# ADuCM355 register map
Vendor: Analog Devices; Series: ADuCM355; File version: 1p0
CPU: CM3 r0p1, little endian, no MPU, no FPU, 3 interrupt priority bits
Registers are 32-bit, read-write, reset 0x0 unless marked. A register's access mark holds for its fields unless they carry their own. Offsets are from the block's base; [hi:lo] are bit positions; {n}, {i} and the like mark numbered series; 'fields as' and 'values as' point back to an identical list.

## AFE
Base 0x400C2000
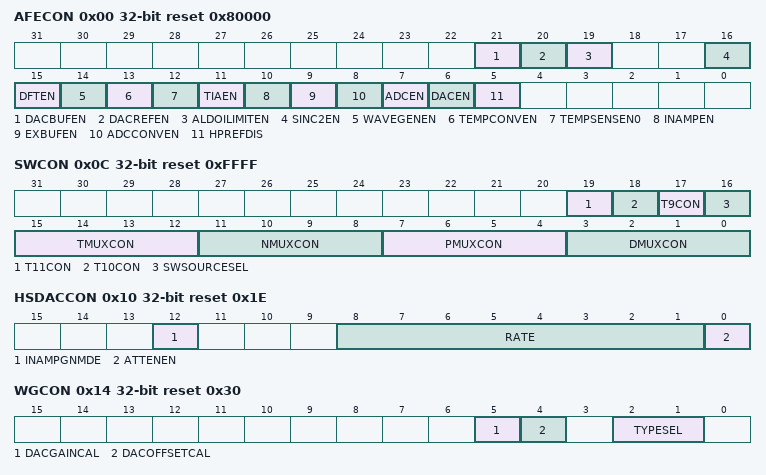
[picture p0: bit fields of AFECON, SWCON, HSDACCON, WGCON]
0x00 AFECON reset 0x80000 — AFE Configuration
  [21] DACBUFEN — Enable DC DAC Buffer
  [20] DACREFEN — High Speed DAC Reference Enable
  [19] ALDOILIMITEN — Analog LDO Current Limiting Enable
  [16] SINC2EN — ADC Output 50/60Hz Filter Enable
  [15] DFTEN — DFT Hardware Accelerator Enable
  [14] WAVEGENEN — Waveform Generator Enable
  [13] TEMPCONVEN — ADC Temp Sensor Convert Enable
  [12] TEMPSENSEN0 — ADC Temperature Sensor Channel Enable
  [11] TIAEN — High Power TIA Enable
  [10] INAMPEN — Enable Excitation Amplifier
  [9] EXBUFEN — Enable Excitation Buffer
  [8] ADCCONVEN — ADC Conversion Start Enable
  [7] ADCEN — ADC Power Enable
  [6] DACEN — High Power DAC Enable
    0=Off (High Power DAC Disabled); 1=On (High Power DAC Enabled)
  [5] HPREFDIS — Disable High Power Reference
0x0C SWCON reset 0xFFFF — Switch Matrix Configuration
  [19] T11CON — Control of T[11]
  [18] T10CON — Control of T[10]
  [17] T9CON — Control of T[9]
  [16] SWSOURCESEL — Switch Control Select
  [15:12] TMUXCON — Control of T Switch MUX.
  [11:8] NMUXCON — Control of N Switch MUX
  [7:4] PMUXCON — Control of P Switch MUX
  [3:0] DMUXCON — Control of D Switch MUX
0x10 HSDACCON reset 0x1E — High Speed DAC Configuration
  [12] INAMPGNMDE — Excitation Amplifier Gain Control
  [8:1] RATE range 0x00000000..0x000000FF — DAC Update Rate
  [0] ATTENEN — PGA Stage Gain Attenuation
0x14 WGCON reset 0x30 — Waveform Generator Configuration
  [5] DACGAINCAL — Bypass DAC Gain
  [4] DACOFFSETCAL — Bypass DAC Offset
  [2:1] TYPESEL — Selects the Type of Waveform
0x30 WGFCW — Waveform Generator - Sinusoid Frequency Control Word
  [23:0] SINEFCW range 0x00000000..0x00FFFFFF — Sinusoid Generator Frequency Control Word
0x34 WGPHASE — Waveform Generator - Sinusoid Phase Offset
  [19:0] SINEOFFSET range 0x00000000..0x000FFFFF — Sinusoid Phase Offset
0x38 WGOFFSET — Waveform Generator - Sinusoid Offset
  [11:0] SINEOFFSET range 0x00000000..0x00000FFF — Sinusoid Offset
0x3C WGAMPLITUDE — Waveform Generator - Sinusoid Amplitude
  [10:0] SINEAMPLITUDE range 0x00000000..0x000007FF — Sinusoid Amplitude
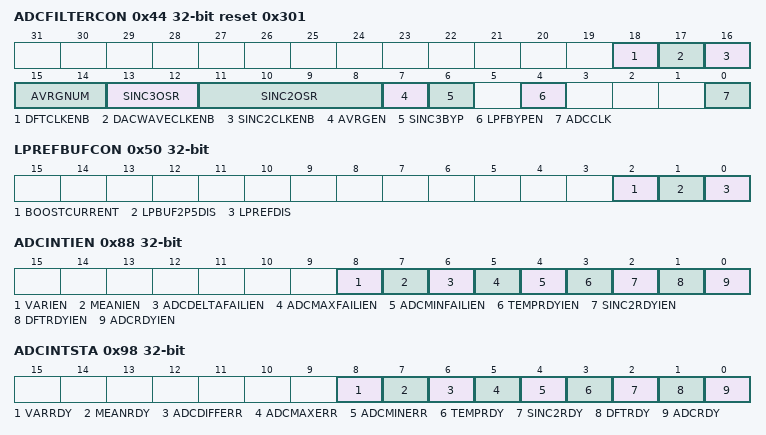
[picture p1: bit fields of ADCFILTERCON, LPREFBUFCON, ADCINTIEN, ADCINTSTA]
0x44 ADCFILTERCON reset 0x301 — ADC Output Filters Configuration
  [18] DFTCLKENB — DFT Clock Enable
  [17] DACWAVECLKENB — DAC Wave Clock Enable
  [16] SINC2CLKENB — SINC2 Filter Clock Enable
  [15:14] AVRGNUM — Number of Samples Averaged
  [13:12] SINC3OSR
  [11:8] SINC2OSR
  [7] AVRGEN — Average Function Enable
  [6] SINC3BYP — SINC3 Filter Bypass
  [4] LPFBYPEN — 50/60Hz Low Pass Filter
  [0] ADCCLK — ADC Data Rate
0x48 HSDACDAT reset 0x800 — HS DAC Code
  [11:0] DACDAT range 0x00000000..0x00000FFF — DAC Code
0x50 LPREFBUFCON
  [2] BOOSTCURRENT — Set: Drive 2 Dac ;Unset Drive 1 Dac, and Save Power
  [1] LPBUF2P5DIS — Low Power Bandgap's Output Buffer
  [0] LPREFDIS — Set This Bit Will Power Down Low Power Bandgap
0x74 ADCDAT — ADC Raw Result
  [15:0] DATA range 0x00000000..0x0000FFFF — ADC Result
0x78 DFTREAL — DFT Result, Real Part
  [17:0] DATA range 0x00000000..0x0003FFFF — DFT Real
0x7C DFTIMAG — DFT Result, Imaginary Part
  [17:0] DATA range 0x00000000..0x0003FFFF — DFT Imaginary
0x80 SINC2DAT — Supply Rejection Filter Result
  [15:0] DATA range 0x00000000..0x0000FFFF — LPF Result
0x84 TEMPSENSDAT — Temperature Sensor Result
  [15:0] DATA range 0x00000000..0x0000FFFF — Temp Sensor
0x88 ADCINTIEN — ADC Interrupt Enable Register
  [8] VARIEN — Variance Interrupt
  [7] MEANIEN — Mean Interrupt
  [6] ADCDELTAFAILIEN — Delta Interrupt
  [5] ADCMAXFAILIEN — ADCMAX Interrupt
  [4] ADCMINFAILIEN — ADCMIN Interrupt
  [3] TEMPRDYIEN — Temp Sensor Interrupt
  [2] SINC2RDYIEN — Low Pass Filter Result Interrupt
  [1] DFTRDYIEN — DFT Result Ready Interrupt
  [0] ADCRDYIEN — ADCDAT Ready Interrupt
0x98 ADCINTSTA — ADC Interrupt Status
  [8] VARRDY — Variance Result Ready
  [7] MEANRDY — Mean Result Ready
  [6] ADCDIFFERR — ADC Delta Ready
  [5] ADCMAXERR — ADC Maximum Value
  [4] ADCMINERR — ADC Minimum Value
  [3] TEMPRDY — Temp Sensor Result Ready
  [2] SINC2RDY — Low Pass Filter Result Status
  [1] DFTRDY — DFT Result Ready Status
  [0] ADCRDY — ADC Result Ready Status
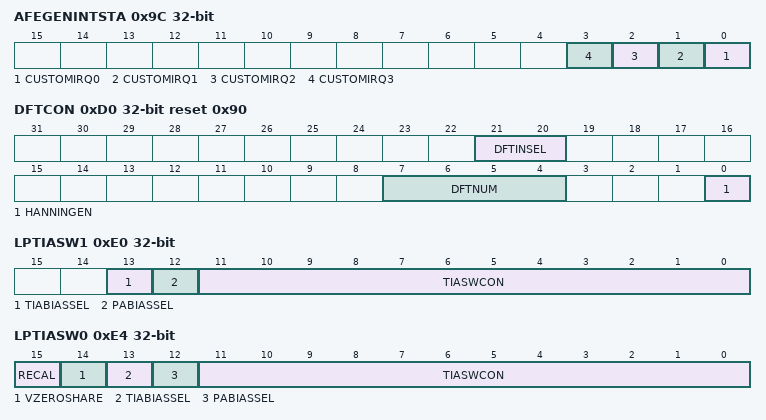
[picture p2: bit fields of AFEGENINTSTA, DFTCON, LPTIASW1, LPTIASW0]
0x9C AFEGENINTSTA — Analog Generation Interrupt
  [n] CUSTOMIRQ{n} (n=0..3)
0xA8 ADCMIN — ADC Minimum Value Check
  [15:0] MINVAL range 0x00000000..0x0000FFFF — ADC Minimum Value Threshold
0xAC ADCMINSM — ADCMIN Hysteresis Value
  [15:0] MINCLRVAL range 0x00000000..0x0000FFFF
0xB0 ADCMAX — ADC Maximum Value Check
  [15:0] MAXVAL range 0x00000000..0x0000FFFF — ADC Max Threshold
0xB4 ADCMAXSMEN — ADCMAX Hysteresis Value
  [15:0] MAXSWEN range 0x00000000..0x0000FFFF
0xB8 ADCDELTA — ADC Delta Value
  [15:0] DELTAVAL range 0x00000000..0x0000FFFF — ADCDAT Code Differences Limit Option
0xBC HPOSCCON reset 0x24 — HPOSC Configuration
  [2] CLK32MHZEN — 16M/32M Output Selector Signal.
0xD0 DFTCON reset 0x90 — AFE DSP Configuration
  [21:20] DFTINSEL — DFT Input Select
  [7:4] DFTNUM — ADC Samples Used
  [0] HANNINGEN — Hanning Window Enable
0xE0 LPTIASW1 — ULPTIA Switch Configuration for Channel 1
  [13] TIABIASSEL — TIA SW13 Control. Active High
  [12] PABIASSEL — TIA SW12 Control. Active High
  [11:0] TIASWCON — TIA SW[11:0] Control
    20=CAPA_LP (CAPA test with LP TIA); 44=NORM (Normal work mode); 45=DIO (Normal work mode with back-back diode enabled.); 46=SHORTSW (Work mode with short switch protection); 108=LOWNOISE (Work mode, vzero-vbias=0.)
0xE4 LPTIASW0 — ULPTIA Switch Configuration for Channel 0
  [15] RECAL — TIA SW15 Control. Active High
  [14] VZEROSHARE — TIA SW14 Control. Active High
  [13] TIABIASSEL — TIA SW13 Control. Active High
  [12] PABIASSEL — TIA SW12 Control. Active High
  [11:0] TIASWCON — TIA SW[11:0] Control
    20=CAPA test with LP TIA; 44=NORM (Normal work mode); 45=DIO (Normal work mode with back-back diode enabled.); 46=SHORTSW (Work mode with short switch protection); 108=LOWNOISE (Work mode, vzero-vbias=0.)
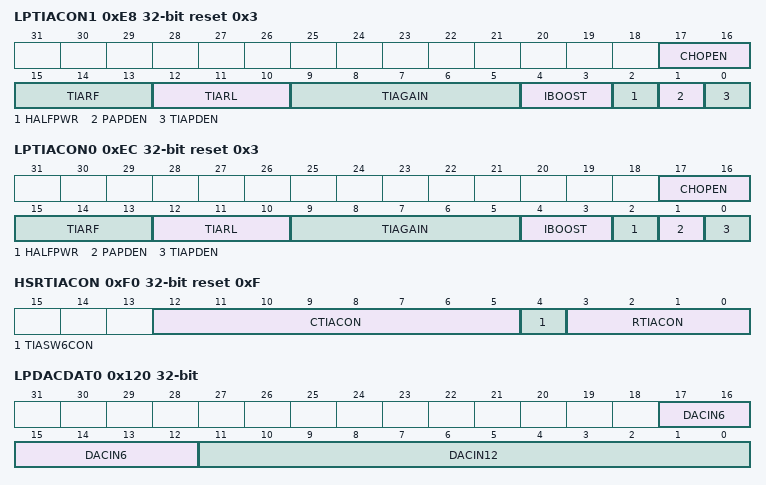
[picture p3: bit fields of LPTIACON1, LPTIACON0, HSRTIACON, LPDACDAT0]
0xE8 LPTIACON1 reset 0x3 — ULPTIA Control Bits Channel 1
  [17:16] CHOPEN — Chopping Enable
  [15:13] TIARF — Set LPF Resistor
    0=DISCONRF (Disconnect TIA output from LPF pin); 1=BYPRF (Bypass resistor); 2=RF20k (20k Ohm); 3=RF100k (100k Ohm); 4=RF200k (200k Ohm); 5=RF400k (400k Ohm); 6=RF600k (600k Ohm); 7=RF1MOHM (1Meg Ohm)
  [12:10] TIARL — Set RLOAD
    0=RL0 (0 ohm); 1=RL10 (10 ohm); 2=RL30 (30 ohm); 3=RL50 (50 ohm); 4=RL100 (100 ohm); 5=RL1p6k (1.6kohm); 6=RL3p1k (3.1kohm); 7=RL3p5k (3.6kohm)
  [9:5] TIAGAIN — Set RTIA Gain Resistor
    0=DISCONTIA (Disconnect TIA Gain resistor); 1=200 Ohm; 2=TIAGAIN1k (1k ohm); 3=TIAGAIN2k (2k); 4=TIAGAIN3k (3k); 5=TIAGAIN4k (4k); 6=TIAGAIN6k (6k); 7=TIAGAIN8k (8k); 8=TIAGAIN10k (10k); 9=TIAGAIN12k (12k); 10=TIAGAIN16k (16k); 11=TIAGAIN20k (20k); 12=TIAGAIN24k (24k); 13=TIAGAIN30k (30k); 14=TIAGAIN32k (32k); 15=TIAGAIN40k (40k); 16=TIAGAIN48k (48k); 17=TIAGAIN64k (64k); 18=TIAGAIN85k (85k); 19=TIAGAIN96k (96k); 20=TIAGAIN100k (100k); 21=TIAGAIN120k (120k); 22=TIAGAIN128k (128k); 23=TIAGAIN160k (160k); 24=TIAGAIN196k (196k); 25=TIAGAIN256k (256k); 26=TIAGAIN512k (512k)
  [4:3] IBOOST — Current Boost Control
  [2] HALFPWR — Half Power Mode Select
  [1] PAPDEN — PA Power Down
  [0] TIAPDEN — TIA Power Down
0xEC LPTIACON0 reset 0x3 — ULPTIA Control Bits Channel 0
  [17:16] CHOPEN — Chopping Enable
  [15:13] TIARF — Set LPF Resistor
    values as LPTIACON1.TIARF
  [12:10] TIARL — Set RLOAD
    values as LPTIACON1.TIARL
  [9:5] TIAGAIN — Set RTIA
    values as LPTIACON1.TIAGAIN
  [4:3] IBOOST — Current Boost Control
  [2] HALFPWR — Half Power Mode Select
  [1] PAPDEN — PA Power Down
  [0] TIAPDEN — TIA Power Down
0xF0 HSRTIACON reset 0xF — High Power RTIA Configuration
  [12:5] CTIACON — Configure Capacitor in Parallel with RTIA
  [4] TIASW6CON — SW6 Control
  [3:0] RTIACON — Configure General RTIA Value
0xF4 DE1RESCON reset 0xFF — DE1 HSTIA Resistors Configuration
  [7:0] DE1RCON range 0x00000000..0x000000FF — DE1 RLOAD RTIA Setting
0xF8 DE0RESCON reset 0xFF — DE0 HSTIA Resistors Configuration
  [7:0] DE0RCON range 0x00000000..0x000000FF — DE0 RLOAD RTIA Setting
0xFC HSTIACON — HSTIA Amplifier Configuration
  [1:0] VBIASSEL — Select HSTIA Positive Input
0x104 DACDCBUFCON — DAC DC Buffer Configuration
  [1] CHANSEL — DAC DC Channel Selection
    0=Chan0 (ULPDAC0 Sets DC level); 1=Chan1 (ULPDAC1 Sets DC level)
0x120 LPDACDAT0 — LPDAC Data-out
  [17:12] DACIN6 — 6BITVAL, 1LSB=34.375mV
  [11:0] DACIN12 — 12BITVAL, 1LSB=537uV
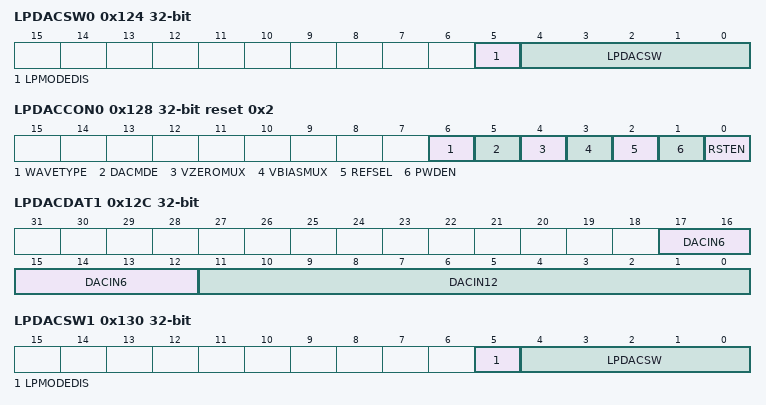
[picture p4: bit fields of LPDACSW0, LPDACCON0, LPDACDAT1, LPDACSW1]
0x124 LPDACSW0 — LPDAC0 Switch Control
  [5] LPMODEDIS — Switch Control
    0=DACCONBIT5 (ULPDAC Switch controlled by ULPDACCON0 bit 5); 1=OVRRIDE (ULPDAC Switches override)
  [4:0] LPDACSW range 0x00000000..0x0000001F — LPDAC0 Switches Matrix
0x128 LPDACCON0 reset 0x2 — LPDAC Control Bits
  [6] WAVETYPE — LPDAC Data Source
    0=MMR (Direct from ULPDACDAT0); 1=WAVEGEN (Waveform generator)
  [5] DACMDE — LPDAC0 Switch Settings
    0=NORM (ULPDAC0 switches set for normal mode); 1=DIAG (ULPDAC0 switches set for Diagnostic mode)
  [4] VZEROMUX — VZERO MUX Select
    0=BITS6 (VZERO 6BIT); 1=BITS12 (VZERO 12BIT)
  [3] VBIASMUX — VBIAS MUX Select
    0=12BIT (Output 12Bit); 1=EN (output 6Bit)
  [2] REFSEL — Reference Select Bit
    0=ULPREF (ULP2P5V Ref); 1=AVDD (AVDD Reference)
  [1] PWDEN — LPDAC0 Power Down
    0=PWREN (ULPDAC0 Powered On); 1=PWRDIS (ULPDAC0 Powered Off)
  [0] RSTEN — Enable Writes to ULPDAC0
    0=WRITEDIS (Disable ULPDAC0 Writes); 1=WRITEEN (Enable ULPDAC0 Writes)
0x12C LPDACDAT1 — Low Power DAC1 data register
  fields as LPDACDAT0
0x130 LPDACSW1 — Control register for switches to LPDAC1
  [5] LPMODEDIS — Switch Control
    0=DACCONBIT5 (ULPDAC Switch controlled by ULPDACCON1 bit 5); 1=OVRRIDE (ULPDAC Switches override)
  [4:0] LPDACSW range 0x00000000..0x0000001F — ULPDAC0 Switches Matrix
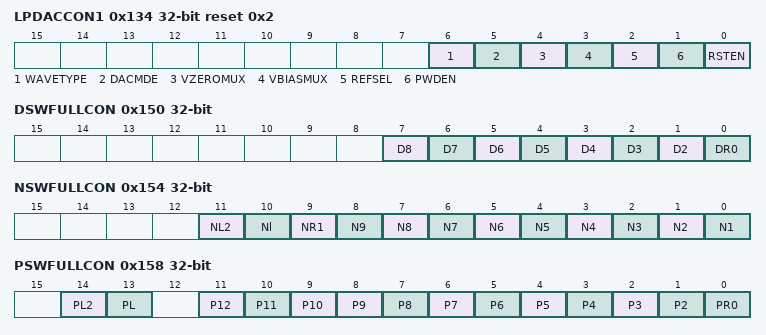
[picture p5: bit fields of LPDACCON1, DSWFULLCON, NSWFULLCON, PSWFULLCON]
0x134 LPDACCON1 reset 0x2 — ULP_DACCON1
  [6] WAVETYPE — DAC Input Source
  [5] DACMDE — LPDAC1 Switch Settings
    0=NORM (ULPDAC1 switches set for normal mode); 1=DIAG (ULPDAC1 switches set for Diagnostic mode)
  [4] VZEROMUX — VZEROOUT
    0=BITS6 (VZERO 6BIT); 1=BITS12 (VZERO 12BIT)
  [3] VBIASMUX — BITSEL
    0=DIS (12BIT Output); 1=EN (6BIT Output)
  [2] REFSEL
    0=ULPREF (Unknown); 1=AVDD (Unknown)
  [1] PWDEN — ULPDAC0 Power
    0=PWREN (ULPDAC1 Powered On); 1=PWRDIS (ULPDAC1 Powered Off)
  [0] RSTEN — Enable Writes to ULPDAC1
    0=WRITEDIS (Disable ULPDAC1 Writes); 1=WRITEEN (Enable ULPDAC1 Writes)
0x150 DSWFULLCON — Switch Matrix Full Configuration (D)
  [n-1] D{n} (n=2..8) — Control of D{n} Switch.
  [0] DR0 — Control of Dr0 Switch.
0x154 NSWFULLCON — Switch Matrix Full Configuration (N)
  [11] NL2 — Control of NL2 Switch.
  [10] Nl — Control of NL Switch.
  [9] NR1 — Control of Nr1 Switch. Set Will Close Nr1, Unset Open
  [n-1] N{n} (n=1..9) — Control of N{n} Switch. Set Will Close N{n}, Unset Open
0x158 PSWFULLCON — Switch Matrix Full Configuration (P)
  [14] PL2 — PL2 Switch Control
  [13] PL — PL Switch Control
  [11] P12 — Control of P12 Switch. Set Will Close P12, Unset Open
  [10] P11 — Control of P11 Switch. Set Will Close P11, Unset Open
  [9] P10 — P10 Switch Control
  [n-1] P{n} (n=2..9) — Control of P{n} Switch. Set Will Close P{n}, Unset Open
  [0] PR0 — PR0 Switch Control
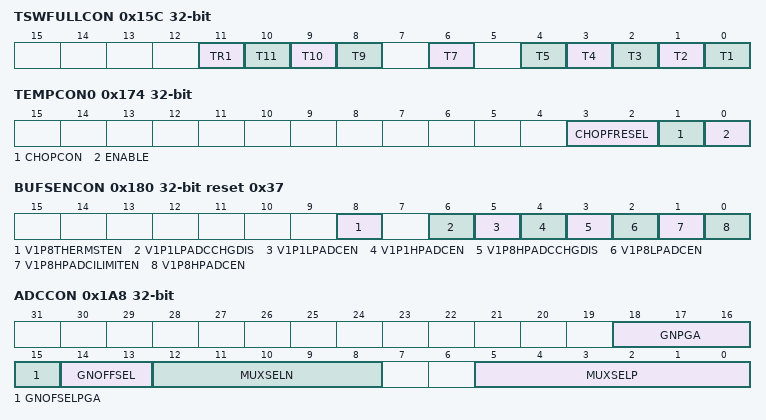
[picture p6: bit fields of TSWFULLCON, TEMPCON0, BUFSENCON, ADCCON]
0x15C TSWFULLCON — Switch Matrix Full Configuration (T)
  [11] TR1 — Control of Tr1 Switch. Set Will Close Tr1, Unset Open
  [10] T11 — Control of T11 Switch. Set Will Close T11, Unset Open
  [9] T10 — Control of T10 Switch. Set Will Close T10, Unset Open
  [8] T9 — Control of T9 Switch. Set Will Close T9, Unset Open
  [6] T7 — Control of T7 Switch. Set Will Close T7, Unset Open
  [n-1] T{n} (n=1..5) — Control of T{n} Switch. Set Will Close T{n}, Unset Open
0x174 TEMPCON0 — Temp Sensor Configuration
  [3:2] CHOPFRESEL — Chop Mode Frequency Setting
  [1] CHOPCON — Temp Sensor Chop Mode
    0=DIS (Disable chop); 1=EN (Enable chop)
  [0] ENABLE — Unused
0x180 BUFSENCON reset 0x37 — HP and LP Buffer Control
  [8] V1P8THERMSTEN — Buffered Reference Output
    0=DIS (Disable 1.8V Buffered Reference output); 1=EN (Enable 1.8V Buffered Reference output)
  [6] V1P1LPADCCHGDIS — Controls Decoupling Cap Discharge Switch
    0=EnChrg (Open switch); 1=DisChrg (Close Switch)
  [5] V1P1LPADCEN — ADC 1.1V LP Buffer
    0=Disable ADC 1.8V LP Reference Buffer; 1=Enable ADC 1.8V LP Reference Buffer
  [4] V1P1HPADCEN — Enable 1.1V HP CM Buffer
    0=Off (Disable 1.1V HP Common Mode Buffer); 1=On (Enable 1.1V HP Common Mode Buffer)
  [3] V1P8HPADCCHGDIS — Controls Decoupling Cap Discharge Switch
    0=Open switch; 1=Closed (Close Switch)
  [2] V1P8LPADCEN — ADC 1.8V LP Reference Buffer
    0=LPADCREF_DIS (Disable LP 1.8V Reference Buffer); 1=LPADCREF_EN (Enable LP 1.8V Reference Buffer)
  [1] V1P8HPADCILIMITEN — HP ADC Input Current Limit
    0=Limit_Dis (Disable buffer Current Limit); 1=Limit_En (Enable buffer Current Limit)
  [0] V1P8HPADCEN — HP 1.8V Reference Buffer
    0=HPBUF_DIS (Disable 1.8V HP ADC Reference Buffer); 1=HPBUF_EN (Enable 1.8V HP ADC Reference Buffer)
0x1A8 ADCCON — ADC Configuration
  [18:16] GNPGA — PGA Gain Setup
  [15] GNOFSELPGA — Internal Offset/Gain Cancellation
  [14:13] GNOFFSEL range 0x00000000..0x00000003 — Obsolete
  [12:8] MUXSELN — Select Negative Input
  [5:0] MUXSELP — Select Positive Input
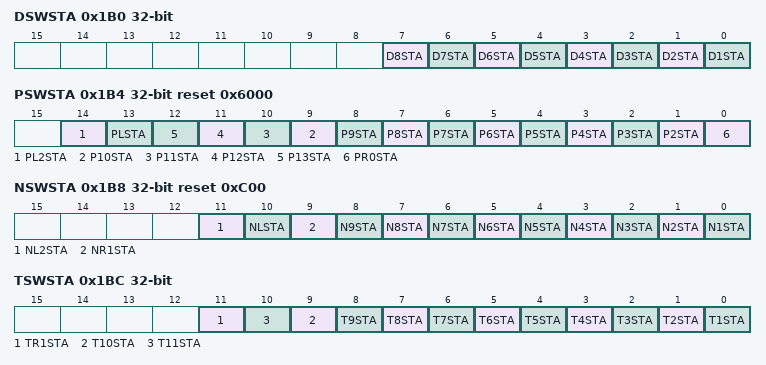
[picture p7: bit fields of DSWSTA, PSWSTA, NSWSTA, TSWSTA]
0x1B0 DSWSTA — Switch Matrix Status (D)
  [n-1] D{n}STA ro (n=2..8) — Status of D{n} Switch.
  [0] D1STA ro — Status of Dr0 Switch.
0x1B4 PSWSTA reset 0x6000 — Switch Matrix Status (P)
  [14] PL2STA ro — PL Switch Control
  [13] PLSTA ro — PL Switch Control
  [n-1] P{n}STA ro (n=2..13) — Status of P{n} Switch.
  [0] PR0STA ro — PR0 Switch Control
0x1B8 NSWSTA reset 0xC00 — Switch Matrix Status (N)
  [11] NL2STA ro — Status of NL2 Switch.
  [10] NLSTA ro — Status of NL Switch.
  [9] NR1STA ro — Status of NR1 Switch.
  [n-1] N{n}STA ro (n=1..9) — Status of N{n} Switch.
0x1BC TSWSTA — Switch Matrix Status (T)
  [11] TR1STA ro — Status of TR1 Switch.
  [n-1] T{n}STA ro (n=1..11) — Status of T{n} Switch.
0x1C0 STATSVAR — Variance Output
  [30:0] VARIANCE ro — Statistical Variance Value
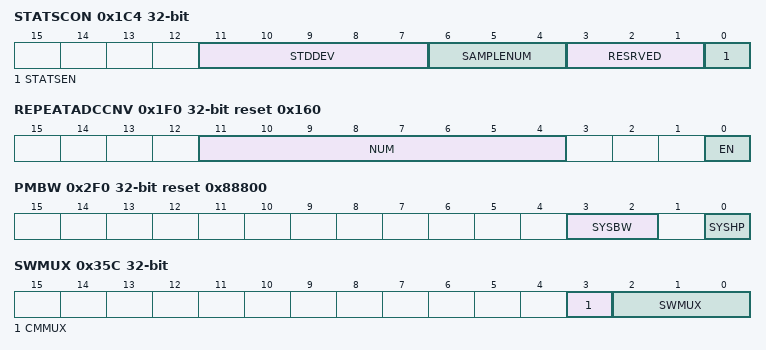
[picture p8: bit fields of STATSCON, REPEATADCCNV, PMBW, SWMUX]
0x1C4 STATSCON — Statistics Control
  [11:7] STDDEV range 0x00000000..0x0000001F — Standard Deviation Configuration
  [6:4] SAMPLENUM — Sample Size
  [3:1] RESRVED range 0x00000000..0x00000007 — Reserved
  [0] STATSEN — Statistics Enable
    0=DIS (Disable Statistics); 1=EN (Enable Statistics)
0x1C8 STATSMEAN — Statistics Mean Output
  [15:0] MEAN ro — Mean Output
0x1F0 REPEATADCCNV reset 0x160 — REPEAT ADC Conversions
  [11:4] NUM range 0x00000000..0x000000FF — Repeat Value
  [0] EN — Enable Repeat ADC Conversions
    0=Dis (Disable Repeat ADC Conversions); 1=En (Enable Repeat ADC Conversions)
0x230 CALDATLOCK — Calibration Data Lock
  [31:0] KEY — Password for Calibration Data Registers
0x234 ADCOFFSETHSTIA — ADC Offset Calibration High Speed TIA Channel
  [14:0] VALUE — HPTIA Offset Calibration
0x238 ADCGAINTEMPSENS0 reset 0x4000 — ADC Gain Calibration Temp Sensor Channel
  [14:0] VALUE — Gain Calibration Temp Sensor Channel
0x23C ADCOFFSETTEMPSENS0 — ADC Offset Calibration Temp Sensor Channel 0
  [14:0] VALUE — Offset Calibration Temp Sensor
0x240 ADCGAINGN1 reset 0x4000 — ADCPGAGN1: ADC Gain Calibration Auxiliary Input Channel
  [14:0] VALUE — Gain Calibration PGA Gain 1x
0x244 ADCOFFSETGN1 — ADC Offset Calibration Auxiliary Channel (PGA Gain=1)
  [14:0] VALUE — Offset Calibration Gain1
0x260 DACGAIN reset 0x800
  [11:0] VALUE — HS DAC Gain Correction Factor
0x264 DACOFFSETATTEN — DAC Offset with Attenuator Enabled (LP Mode)
  [11:0] VALUE — DAC Offset Correction Factor
0x268 DACOFFSET — DAC Offset with Attenuator Disabled (LP Mode)
  [11:0] VALUE — DAC Offset Correction Factor
0x270 ADCGAINGN1P5 reset 0x4000 — ADC Gain Calibration Auxiliary Input Channel (PGA Gain=1.5)
  [14:0] VALUE — Gain Calibration PGA Gain 1.5x
0x274 ADCGAINGN2 reset 0x4000 — ADC Gain Calibration Auxiliary Input Channel (PGA Gain=2)
  [14:0] VALUE — Gain Calibration PGA Gain 2x
0x278 ADCGAINGN4 reset 0x4000 — ADC Gain Calibration Auxiliary Input Channel (PGA Gain=4)
  [14:0] VALUE — Gain Calibration PGA Gain 4x
0x280 ADCPGAOFFSETCANCEL — ADC Offset Cancellation (Optional)
  [14:0] OFFSETCANCEL — Offset Cancellation
0x284 ADCGNHSTIA reset 0x4000 — ADC Gain Calibration for HS TIA Channel
  [14:0] VALUE — Gain Error Calibration HS TIA Channel
0x288 ADCOFFSETLPTIA0 — ADC Offset Calibration ULP-TIA0 Channel
  [14:0] VALUE — Offset Calibration for ULP-TIA0
0x28C ADCGNLPTIA0 reset 0x4000 — ADC GAIN Calibration for LP TIA0 Channel
  [14:0] VALUE — Gain Error Calibration ULPTIA0
0x294 ADCPGAGN4OFCAL reset 0x4000 — ADC Gain Calibration with DC Cancellation(PGA G=4)
  [14:0] ADCGAINAUX range 0x00000000..0x00007FFF — DC Calibration Gain=4
0x298 ADCGAINGN9 reset 0x4000 — ADC Gain Calibration Auxiliary Input Channel (PGA Gain=9)
  [14:0] VALUE — Gain Calibration PGA Gain 9x
0x2A8 ADCOFFSETEMPSENS1 — ADC Offset Calibration Temp Sensor Channel 1
  [14:0] VALUE — Offset Calibration Temp Sensor
0x2AC ADCGAINTEMPSENS1 reset 0x4000 — ADC Gain Calibration Temperature Sensor Channel
  [14:0] VALUE — Gain Calibration for Diode Temp Sensor
0x2B8 DACOFFSETATTENHP — DAC Offset with Attenuator Enabled (HP Mode)
  [11:0] VALUE — DAC Offset Correction Factor
0x2BC DACOFFSETHP — DAC Offset with Attenuator Disabled (HP Mode)
  [11:0] VALUE — DAC Offset Correction Factor
0x2C0 ADCOFFSETLPTIA1 — ADC Offset Calibration LP TIA1 Channel
  [14:0] VALUE — Offset Calibration for ULP-TIA1
0x2C4 ADCGNLPTIA1 reset 0x4000 — ADC GAIN Calibration for LP TIA1 Channel
  [14:0] ULPTIA1GN — Gain Calibration ULP-TIA1
0x2C8 ADCOFFSETGN2 — Offset Calibration Auxiliary Channel (PGA Gain =2)
  [14:0] VALUE
0x2CC ADCOFFSETGN1P5 — Offset Calibration Auxiliary Channel (PGA Gain =1.5)
  [14:0] VALUE — Offset Calibration Gain1.5
0x2D0 ADCOFFSETGN9 — Offset Calibration Auxiliary Channel (PGA Gain =9)
  [14:0] VALUE — Offset Calibration Gain9
0x2D4 ADCOFFSETGN4 — Offset Calibration Auxiliary Channel (PGA Gain =4)
  [14:0] VALUE — Offset Calibration Gain4
0x2F0 PMBW reset 0x88800 — Power Mode Configuration
  [3:2] SYSBW — Configure System Bandwidth
    0=BWNA (no action for system configuration); 1=BW50 (50kHz -3dB bandwidth); 2=BW100 (100kHz -3dB bandwidth); 3=BW250 (250kHz -3dB bandwidth)
  [0] SYSHP — Set High Speed DAC and ADC in High Power Mode
    0=LP (LP mode); 1=HP (HP mode)
0x35C SWMUX — Switch Mux for ECG
  [3] CMMUX — CM Resistor Select for Ain2, Ain3
  [2:0] SWMUX — ECG Swmux Control
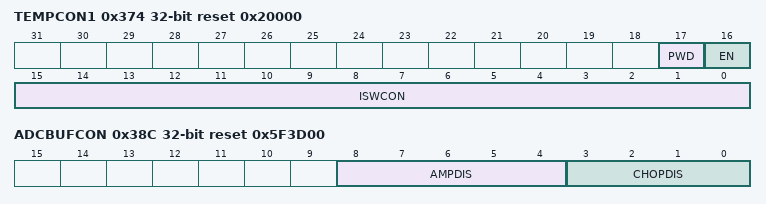
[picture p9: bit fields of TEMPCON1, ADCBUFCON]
0x374 TEMPCON1 reset 0x20000 — AFE_TEMPSEN_DIO
  [17] PWD — Power Down Control
    0=Active (Unknown); 1=PowerDown (Unknown)
  [16] EN — Test Signal Enable
    0=On (Turn On); 1=Off (Turn Off)
  [15:0] ISWCON range 0x00000000..0x0000FFFF — Bias Current Selection
0x388 TESTDAC — DAC Test
  [2] LPFBYPEN — Bypass Low Pass Filter Between Dac and Buffer
0x38C ADCBUFCON reset 0x5F3D00 — Configure ADC Input Buffer
  [8:4] AMPDIS range 0x00000000..0x0000001F — Disable OpAmp.
  [3:0] CHOPDIS range 0x00000000..0x0000000F — Disable Chop
